AUTOSAR XML (schema 00050)
package /BMW/Boardnet/CommunicationClusters
  can cluster CAN_IPF_32: baudrate=500000, protocol-name=CAN
    can physical channel CAN_IPF_32: comm-connectors=[con_IPF_HVM_CAN_IPF_32, con_Wallbox_CHAdeMO_CAN_IPF_32]
      frame EAPC_CHDM_H100: id 0x100, from IPF_HVM, to Wallbox_CHAdeMO, category=APPLICATION, frame-length=8, can-addressing-mode=STANDARD, can-frame-rx-behavior=CAN-20, can-frame-tx-behavior=CAN-20
        pdu EAPC_CHDM_H100: length=8, transmission-mode-true-timing=cyclic-timing=time-period={tolerance=absolute-tolerance=0.01, value=0.1}, unused-bit-pattern=255  # @Symphony.CustomCommModePduGroup=EAPC_CHDM;
          signal EAPC_CHDM_MAX_BT_U: start 32, 8 bit, little-endian, data-type-policy=OVERRIDE, base-type=uint16, compu {identical; unit V} "EAPC_ChademoMaximumBatteryVoltage", range phys 0..600 V, to Wallbox_CHAdeMO  # EAPC_ChademoMaximumBatteryVoltage | LogicalInterface:BMW.INFRASTRUCTURE.HIGHVOLTAGE.Charging[internal]@Infrastruktur;
          mapping EAPC_CHDM_CHA_RATE_REF_CONST: i-signal=EAPC_CHDM_CHA_RATE_REF_CONST, packing-byte-order=little-endian, start-position=48
          signal EAPC_CHDM_CHA_RATE_TEST_GREE: start 8, 8 bit, little-endian, base-type=uint8
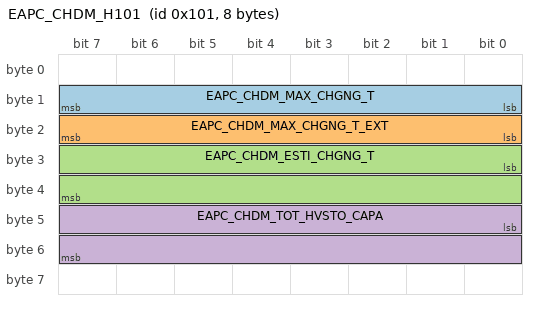
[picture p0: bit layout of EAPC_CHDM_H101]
      frame EAPC_CHDM_H101: id 0x101, from IPF_HVM, to Wallbox_CHAdeMO, category=APPLICATION, frame-length=8, can-addressing-mode=STANDARD, can-frame-rx-behavior=CAN-20, can-frame-tx-behavior=CAN-20
        pdu EAPC_CHDM_H101: length=8, transmission-mode-true-timing=cyclic-timing=time-period={tolerance=absolute-tolerance=0.01, value=0.1}, unused-bit-pattern=255  # @Symphony.CustomCommModePduGroup=EAPC_CHDM;
          signal EAPC_CHDM_MAX_CHGNG_T: start 8, 8 bit, little-endian, base-type=uint8, compu {phys=raw*10 for raw 0..255; unit s} "EAPC_ChademoMaximumChargingTime", range phys 0..2550 s, to Wallbox_CHAdeMO  # EAPC_ChademoMaximumChargingTime | LogicalInterface:BMW.INFRASTRUCTURE.HIGHVOLTAGE.Charging[internal]@Infrastruktur;
          signal EAPC_CHDM_MAX_CHGNG_T_EXT: start 16, 8 bit, little-endian, base-type=uint8, compu {identical; unit min} "EAPC_ChademoMaximumChargingTimeExtended", range phys 0..255 min, to Wallbox_CHAdeMO  # EAPC_ChademoMaximumChargingTimeExtended | LogicalInterface:BMW.INFRASTRUCTURE.HIGHVOLTAGE.Charging[internal]@Infrastruktur; Dieses Signal wird nur ausgewertet, wenn das Signal <<Maximum Charging Time>> den Wert FF aufweist. ========== LogicalInterface:BMW.INFRASTRUCTURE.HIGHVOLTAGE.Charging[internal]@Infrastruktur; This signal is evaluated only if the signal <<Maximum Charging Time>> has the value FF.
          signal EAPC_CHDM_ESTI_CHGNG_T: start 24, 16 bit, little-endian, base-type=uint16, compu {identical; unit min} "EAPC_ChademoEstimatedChargingTime", range phys 0..254 min, to Wallbox_CHAdeMO  # EAPC_ChademoEstimatedChargingTime | LogicalInterface:BMW.INFRASTRUCTURE.HIGHVOLTAGE.Charging[internal]@Infrastruktur; Dieses Signal wird nur für die Anzeige ausgewertet. Erwartete Zeitdauer bis zum Ladeende. ========== LogicalInterface:BMW.INFRASTRUCTURE.HIGHVOLTAGE.Charging[internal]@Infrastruktur; This signal is evaluated only for the display. Expected duration until the end of charging.
          signal EAPC_CHDM_TOT_HVSTO_CAPA: start 40, 16 bit, little-endian, base-type=uint16, compu {phys=raw*0.1 for raw 0..65535; unit kWh}, range phys 0..6553.5 kWh, to Wallbox_CHAdeMO  # EAPC_ChademoTotalCapacityOfTractionBatt | LogicalInterface:BMW.INFRASTRUCTURE.HIGHVOLTAGE.Charging[internal]@Infrastruktur; Kapazität des HV-Speichers ========== LogicalInterface:BMW.INFRASTRUCTURE.HIGHVOLTAGE.Charging[internal]@Infrastruktur; Capacitance of the high voltage battery
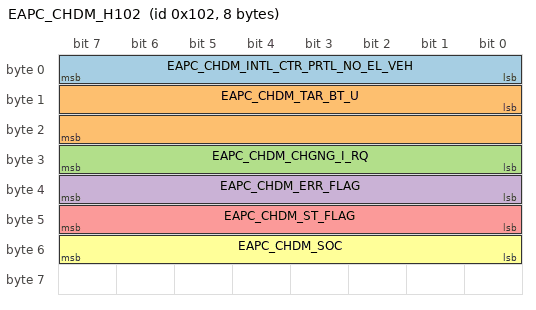
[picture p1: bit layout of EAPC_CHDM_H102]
      frame EAPC_CHDM_H102: id 0x102, from IPF_HVM, to Wallbox_CHAdeMO, category=APPLICATION, frame-length=8, can-addressing-mode=STANDARD, can-frame-rx-behavior=CAN-20, can-frame-tx-behavior=CAN-20
        pdu EAPC_CHDM_H102: length=8, transmission-mode-true-timing=cyclic-timing=time-period={tolerance=absolute-tolerance=0.01, value=0.1}, unused-bit-pattern=255  # @Symphony.CustomCommModePduGroup=EAPC_CHDM;
          signal EAPC_CHDM_INTL_CTR_PRTL_NO_EL_VEH: start 0, 8 bit, little-endian, base-type=uint8, compu {identical} "EAPC_ChademoInternalControlProtokolNumberElectricVehicle", range phys 0..255, to Wallbox_CHAdeMO  # EAPC_ChademoInternalControlProtocolNumberElectricVehicle | LogicalInterface:BMW.INFRASTRUCTURE.HIGHVOLTAGE.Charging[internal]@Infrastruktur;
          signal EAPC_CHDM_TAR_BT_U: start 8, 16 bit, little-endian, base-type=uint16, compu {identical; unit V} "EAPC_ChademoTargetBatteryVoltage", range phys 0..600 V, to Wallbox_CHAdeMO  # EAPC_ChademoTargetBatteryVoltage | LogicalInterface:BMW.INFRASTRUCTURE.HIGHVOLTAGE.Charging[internal]@Infrastruktur;
          signal EAPC_CHDM_CHGNG_I_RQ: start 24, 8 bit, little-endian, base-type=uint8, compu {identical; unit A} "EAPC_ChademoChargingCurrentRequest", range phys 0..255 A, to Wallbox_CHAdeMO  # EAPC_ChademoChargingCurrentRequest | LogicalInterface:BMW.INFRASTRUCTURE.HIGHVOLTAGE.Charging[internal]@Infrastruktur;
          signal EAPC_CHDM_ERR_FLAG: start 32, 8 bit, little-endian, base-type=uint8, compu {mask 1: 1=Battery_overvoltage (EAPC_CHDM_ERR_FLAG_Battery_overvoltage) ((0: normal, 1: occurrence)), mask 16: 16=Voltage_differential (EAPC_CHDM_ERR_FLAG_Voltage_differential) ((0: normal, 1: occurrence)), mask 2: 2=Battery_undervoltage (EAPC_CHDM_ERR_FLAG_Battery_undervoltage) ((0: normal, 1: occurrence)), mask 4: 4=Battery_current_differential (EAPC_CHDM_ERR_FLAG_Battery_current_differential) ((0: normal, 1: occurrence)), mask 8: 8=High_battery_temperature (EAPC_CHDM_ERR_FLAG_High_battery_temperature) ((0: normal, 1: occurrence))} "EAPC_ChademoErrorFlag", to Wallbox_CHAdeMO  # EAPC_ChademoErrorFlag | LogicalInterface:BMW.INFRASTRUCTURE.HIGHVOLTAGE.Charging[internal]@Infrastruktur;
          signal EAPC_CHDM_ST_FLAG: start 40, 8 bit, little-endian, base-type=uint8, compu {mask 1: 1=Vehicle_charging_enabled (EAPC_CHDM_ST_FLAG_Vehicle_charging_enabled) ((0: disenabled, 1: enabled)), mask 16: 16=Normal_stop_request_before_charging (EAPC_CHDM_ST_FLAG_Normal_stop_request_before_charging) ((0: No request 1: Stop request)), mask 2: 2=Vehicle_shift_position (EAPC_CHDM_ST_FLAG_Vehicle_shift_position) ((0: parking position, 1: other than the parking)), mask 4: 4=Charging_System_Fault (EAPC_CHDM_ST_FLAG_Charging_System_Fault) ((0: normal, 1:fault )), mask 8: 8=Vehicle_status (EAPC_CHDM_ST_FLAG_Vehicle_status) ((0: EV contactor close or during welding detection 1: EV contactor open or termination of welding detection))} "EAPC_ChademoStatusFlag", to Wallbox_CHAdeMO  # EAPC_ChademoStatusFlag | LogicalInterface:BMW.INFRASTRUCTURE.HIGHVOLTAGE.Charging[internal]@Infrastruktur;
          signal EAPC_CHDM_SOC: start 48, 8 bit, little-endian, base-type=uint8, compu {identical; unit %} "EAPC_ChademoRemainingQuantityBatteryCapacity", range phys 0..100 %, to Wallbox_CHAdeMO  # EAPC_ChademoStateOfCharge | LogicalInterface:BMW.INFRASTRUCTURE.HIGHVOLTAGE.Charging[internal]@Infrastruktur; Charged rate ========== LogicalInterface:BMW.INFRASTRUCTURE.HIGHVOLTAGE.Charging[internal]@Infrastruktur; Charged rate
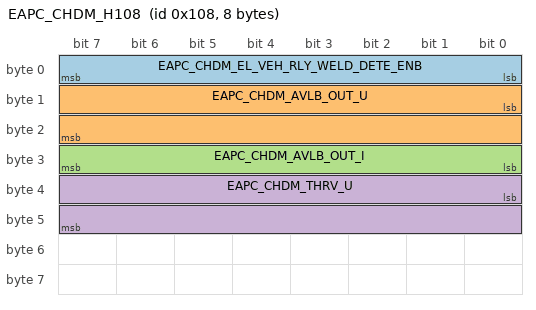
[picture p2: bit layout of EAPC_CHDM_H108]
      frame EAPC_CHDM_H108: id 0x108, from Wallbox_CHAdeMO, to IPF_HVM, category=APPLICATION, frame-length=8, can-addressing-mode=STANDARD, can-frame-rx-behavior=CAN-20, can-frame-tx-behavior=CAN-20
        pdu EAPC_CHDM_H108: length=8, transmission-mode-true-timing=cyclic-timing=time-period={tolerance=absolute-tolerance=0.01, value=0.1}, unused-bit-pattern=255  # @Symphony.CustomCommModePduGroup=EAPC_CHDM;
          signal EAPC_CHDM_EL_VEH_RLY_WELD_DETE_ENB: start 0, 8 bit, little-endian, base-type=uint8, compu {identical} "EAPC_ChademoElectricVehicleRelayWeldingDetectionEnable", range phys 0..255, to IPF_HVM CCU  # EAPC_ChademoElectricVehicleRelayWeldingDetectionEnable | LogicalInterface:BMW.INFRASTRUCTURE.HIGHVOLTAGE.Charging[internal]@Infrastruktur;
          signal EAPC_CHDM_AVLB_OUT_U: start 8, 16 bit, little-endian, base-type=uint16, compu {identical; unit V} "EAPC_ChademoAvailableOutputVoltage", range phys 0..600 V, to IPF_HVM CCU  # EAPC_ChademoAvailableOutputVoltage | LogicalInterface:BMW.INFRASTRUCTURE.HIGHVOLTAGE.Charging[internal]@Infrastruktur;
          signal EAPC_CHDM_AVLB_OUT_I: start 24, 8 bit, little-endian, base-type=uint8, compu {identical; unit A} "EAPC_ChademoAvailableOutputCurrent", range phys 0..255 A, to IPF_HVM CCU  # EAPC_ChademoAvailableOutputCurrent | LogicalInterface:BMW.INFRASTRUCTURE.HIGHVOLTAGE.Charging[internal]@Infrastruktur;
          signal EAPC_CHDM_THRV_U: start 32, 16 bit, little-endian, base-type=uint16, compu {identical; unit V} "EAPC_ChademoThresholdValueVoltage", range phys 0..600 V, to IPF_HVM CCU  # EAPC_ChademoThresholdValueVoltage | LogicalInterface:BMW.INFRASTRUCTURE.HIGHVOLTAGE.Charging[internal]@Infrastruktur;
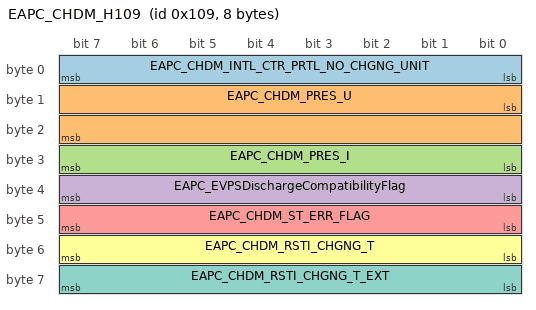
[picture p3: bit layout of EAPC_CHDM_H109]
      frame EAPC_CHDM_H109: id 0x109, from Wallbox_CHAdeMO, to IPF_HVM, category=APPLICATION, frame-length=8, can-addressing-mode=STANDARD, can-frame-rx-behavior=CAN-20, can-frame-tx-behavior=CAN-20
        pdu EAPC_CHDM_H109: length=8, transmission-mode-true-timing=cyclic-timing=time-period={tolerance=absolute-tolerance=0.01, value=0.1}, unused-bit-pattern=255  # @Symphony.CustomCommModePduGroup=EAPC_CHDM;
          signal EAPC_CHDM_INTL_CTR_PRTL_NO_CHGNG_UNIT: start 0, 8 bit, little-endian, base-type=uint8, compu {identical} "EAPC_ChademoInternalControlProtokolNumberChargingUnit", range phys 0..255, to IPF_HVM CCU  # EAPC_ChademoInternalControlProtokolNumberChargingUnit | LogicalInterface:BMW.INFRASTRUCTURE.HIGHVOLTAGE.Charging[internal]@Infrastruktur;
          signal EAPC_CHDM_PRES_U: start 8, 16 bit, little-endian, base-type=uint16, compu {identical; unit V} "EAPC_ChademoPresentVoltage", range phys 0..600 V, to IPF_HVM CCU  # EAPC_ChademoPresentVoltage | LogicalInterface:BMW.INFRASTRUCTURE.HIGHVOLTAGE.Charging[internal]@Infrastruktur;
          signal EAPC_CHDM_PRES_I: start 24, 8 bit, little-endian, base-type=uint8, compu {identical; unit A} "EAPC_ChademoPresentCurrent", range phys 0..255 A, to IPF_HVM CCU  # EAPC_ChademoPresentCurrent | LogicalInterface:BMW.INFRASTRUCTURE.HIGHVOLTAGE.Charging[internal]@Infrastruktur;
          signal EAPC_EVPSDischargeCompatibilityFlag: start 32, 8 bit, little-endian, base-type=uint8, invalid-value=value_255:255, compu {0=Incompatible (EAPC_EVPSDischargeCompatibilityFlag_Incompatible), 1=Compatible (EAPC_EVPSDischargeCompatibilityFlag_Compatible)}, range raw 0..1, to CCU  # Entladungskompatibilitätsflag EVPS; ========== Discharge compatibility flag EVPS
          signal EAPC_CHDM_ST_ERR_FLAG: start 40, 8 bit, little-endian, base-type=uint8, compu {mask 1: 1=Charger_status (EAPC_CHDM_ST_ERR_FLAG_Charger_status) ((0: standby, 1: charging)), mask 16: 16=Charging_system_malfunction (EAPC_CHDM_ST_ERR_FLAG_Charging_system_malfunction) ((0: normal, 1: malfunction)), mask 2: 2=Charger_malfunction (EAPC_CHDM_ST_ERR_FLAG_Charger_malfunction) ((0: normal, 1: malfunction)), mask 32: 32=Charging_stop_control (EAPC_CHDM_ST_ERR_FLAG_Charging_stop_control) ((0: trucking mode, 1: suppressing mode)), mask 4: 4=Charger_connector_lock (EAPC_CHDM_ST_ERR_FLAG_Charger_connector_lock) ((0: open, 1: locked)), mask 8: 8=Battery_incompatibility (EAPC_CHDM_ST_ERR_FLAG_Battery_incompatibility) ((0: compatible, 1: incompatible))} "EAPC_ChademoStatusErrorFlag", to IPF_HVM CCU  # EAPC_ChademoStatusErrorFlag | LogicalInterface:BMW.INFRASTRUCTURE.HIGHVOLTAGE.Charging[internal]@Infrastruktur;
          signal EAPC_CHDM_RSTI_CHGNG_T: start 48, 8 bit, little-endian, base-type=uint8, compu {phys=raw*10 for raw 0..255; unit s} "EAPC_ChademoResidualTimeChargingTime", range phys 0..2550 s, to IPF_HVM CCU  # EAPC_ChademoResidualTimeChargingTime | LogicalInterface:BMW.INFRASTRUCTURE.HIGHVOLTAGE.Charging[internal]@Infrastruktur;
          signal EAPC_CHDM_RSTI_CHGNG_T_EXT: start 56, 8 bit, little-endian, base-type=uint8, compu {identical; unit min} "EAPC_ChademoResidualTimeChargingTimeExtended", range phys 0..255 min, to IPF_HVM CCU  # EAPC_ChademoResidualTimeChargingTimeExtended | LogicalInterface:BMW.INFRASTRUCTURE.HIGHVOLTAGE.Charging[internal]@Infrastruktur;
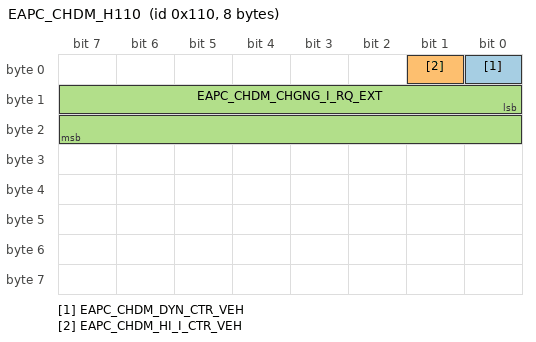
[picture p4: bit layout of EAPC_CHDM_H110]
      frame EAPC_CHDM_H110: id 0x110, from IPF_HVM, to Wallbox_CHAdeMO, category=APPLICATION, frame-length=8, can-addressing-mode=STANDARD, can-frame-rx-behavior=CAN-20, can-frame-tx-behavior=CAN-20
        pdu EAPC_CHDM_H110: length=8, transmission-mode-true-timing=cyclic-timing=time-period={tolerance=absolute-tolerance=0.01, value=0.1}, unused-bit-pattern=255  # @Symphony.CustomCommModePduGroup=EAPC_CHDM;
          signal EAPC_CHDM_DYN_CTR_VEH: start 0, 1 bit, little-endian, base-type=uint8, compu-method=EAPC_CHAdeMO_1, range raw 0..1, to Wallbox_CHAdeMO  # EAPC_ChademoDynamicControlVehicle | LogicalInterface:BMW.INFRASTRUCTURE.HIGHVOLTAGE.Charging[internal]@Infrastruktur; Unterstützung dynamische Regelung durch Fahrzeug ========== LogicalInterface:BMW.INFRASTRUCTURE.HIGHVOLTAGE.Charging[internal]@Infrastruktur; Support of dynamic control through vehicle
          signal EAPC_CHDM_HI_I_CTR_VEH: start 1, 1 bit, little-endian, base-type=uint8, compu-method=EAPC_CHAdeMO_1, range raw 0..1, to Wallbox_CHAdeMO  # EAPC_ChademoHighCurrentControlVehicle | LogicalInterface:BMW.INFRASTRUCTURE.HIGHVOLTAGE.Charging[internal]@Infrastruktur; Unterstützung hoher Ladeströme durch Fahrzeug ========== LogicalInterface:BMW.INFRASTRUCTURE.HIGHVOLTAGE.Charging[internal]@Infrastruktur; Support of high charging currents through vehicle
          signal EAPC_CHDM_CHGNG_I_RQ_EXT: start 8, 16 bit, little-endian, base-type=uint16, compu {identical; unit A}, range phys 0..1023 A, to Wallbox_CHAdeMO  # EAPC_ChademoChargingCurrentRequestExt | LogicalInterface:BMW.INFRASTRUCTURE.HIGHVOLTAGE.Charging[internal]@Infrastruktur; Angeforderder Ladestrom ========== LogicalInterface:BMW.INFRASTRUCTURE.HIGHVOLTAGE.Charging[internal]@Infrastruktur; Requested charging current
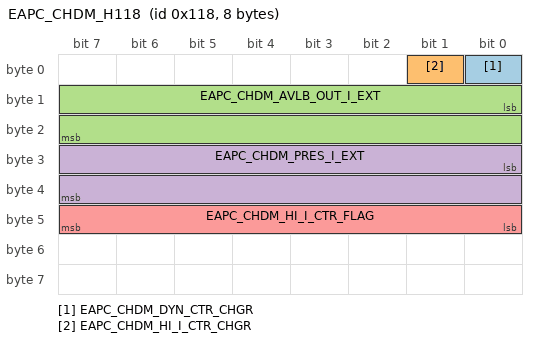
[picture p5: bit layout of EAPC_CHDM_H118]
      frame EAPC_CHDM_H118: id 0x118, from Wallbox_CHAdeMO, to IPF_HVM, category=APPLICATION, frame-length=8, can-addressing-mode=STANDARD, can-frame-rx-behavior=CAN-20, can-frame-tx-behavior=CAN-20
        pdu EAPC_CHDM_H118: length=8, transmission-mode-true-timing=cyclic-timing=time-period={tolerance=absolute-tolerance=0.01, value=0.1}, unused-bit-pattern=255  # @Symphony.CustomCommModePduGroup=EAPC_CHDM;
          signal EAPC_CHDM_DYN_CTR_CHGR: start 0, 1 bit, little-endian, base-type=uint8, compu-method=EAPC_CHAdeMO_1, range raw 0..1, to IPF_HVM CCU  # EAPC_ChademoDynamicControlCharger | LogicalInterface:BMW.INFRASTRUCTURE.HIGHVOLTAGE.Charging[internal]@Infrastruktur; Unterstützung dynamische Regelung durch Ladestation ========== LogicalInterface:BMW.INFRASTRUCTURE.HIGHVOLTAGE.Charging[internal]@Infrastruktur; Support of dynamic control through charging station
          signal EAPC_CHDM_HI_I_CTR_CHGR: start 1, 1 bit, little-endian, base-type=uint8, compu-method=EAPC_CHAdeMO_1, range raw 0..1, to IPF_HVM CCU  # EAPC_ChademoHighCurrentControlCharger | LogicalInterface:BMW.INFRASTRUCTURE.HIGHVOLTAGE.Charging[internal]@Infrastruktur; Unterstützung hoher Ladeströme durch Ladestation ========== LogicalInterface:BMW.INFRASTRUCTURE.HIGHVOLTAGE.Charging[internal]@Infrastruktur; Support of high charging currents through charging station
          signal EAPC_CHDM_AVLB_OUT_I_EXT: start 8, 16 bit, little-endian, base-type=uint16, compu {identical; unit A}, range phys 0..1023 A, to IPF_HVM CCU  # EAPC_ChademoAvailableOutputCurrentExt | LogicalInterface:BMW.INFRASTRUCTURE.HIGHVOLTAGE.Charging[internal]@Infrastruktur; Verfügbarer Ladestrom ========== LogicalInterface:BMW.INFRASTRUCTURE.HIGHVOLTAGE.Charging[internal]@Infrastruktur; Available charging current
          signal EAPC_CHDM_PRES_I_EXT: start 24, 16 bit, little-endian, base-type=uint16, compu {identical; unit A}, range phys 0..1023 A, to IPF_HVM CCU  # EAPC_ChademoPresentChargingCurrentExt | LogicalInterface:BMW.INFRASTRUCTURE.HIGHVOLTAGE.Charging[internal]@Infrastruktur; Aktueller Ladestrom ========== LogicalInterface:BMW.INFRASTRUCTURE.HIGHVOLTAGE.Charging[internal]@Infrastruktur; Current charging current
          signal EAPC_CHDM_HI_I_CTR_FLAG: start 40, 8 bit, little-endian, base-type=uint8, compu {mask 1: 1=Operating_condition (EAPC_HighCurrentControlCondFlags_Operating_condition), mask 16: 16=Current_limiting_function_charging_connector (EAPC_HighCurrentControlCondFlags_Current_limiting_function_charging_connector), mask 2: 2=Cooling_function_charging_cable (EAPC_HighCurrentControlCondFlags_Cooling_function_charging_cable), mask 32: 32=Over_temperature_protection_charging_connector (EAPC_HighCurrentControlCondFlags_Over_temperature_protection_charging_connector), mask 4: 4=Current_limiting_function_charging_cable (EAPC_HighCurrentControlCondFlags_Current_limiting_function_charging_cable), mask 64: 64=Reliability_design_temperature_monitoring (EAPC_HighCurrentControlCondFlags_Reliability_design_temperature_monitoring), mask 8: 8=Cooling_function_charging_connector (EAPC_HighCurrentControlCondFlags_Cooling_function_charging_connector)}, to IPF_HVM CCU  # EAPC_ChademoHighCurrentControlCondFlags | LogicalInterface:BMW.INFRASTRUCTURE.HIGHVOLTAGE.Charging[internal]@Infrastruktur; Flags zur Überwachung des Hochstromladens ========== LogicalInterface:BMW.INFRASTRUCTURE.HIGHVOLTAGE.Charging[internal]@Infrastruktur; Flags for monitoring the high-current charging
  can cluster EAPC_DC_CAN: baudrate=500000, protocol-name=CAN
    can physical channel EAPC_DC_CAN: comm-connectors=[con_CCU_EAPC_DC_CAN, con_Wallbox_CHAdeMO_EAPC_DC_CAN]
      frame EAPC_CHDM_H100: id 0x100, from CCU, to Wallbox_CHAdeMO, category=APPLICATION, frame-length=8, can-addressing-mode=STANDARD, can-frame-rx-behavior=CAN-20, can-frame-tx-behavior=CAN-20
        carries pdu EAPC_CHDM_H100: packing-byte-order=little-endian, start-position=0
      frame EAPC_CHDM_H101: id 0x101, from CCU, to Wallbox_CHAdeMO, category=APPLICATION, frame-length=8, can-addressing-mode=STANDARD, can-frame-rx-behavior=CAN-20, can-frame-tx-behavior=CAN-20
        carries pdu EAPC_CHDM_H101: packing-byte-order=little-endian, start-position=0
      frame EAPC_CHDM_H102: id 0x102, from CCU, to Wallbox_CHAdeMO, category=APPLICATION, frame-length=8, can-addressing-mode=STANDARD, can-frame-rx-behavior=CAN-20, can-frame-tx-behavior=CAN-20
        carries pdu EAPC_CHDM_H102: packing-byte-order=little-endian, start-position=0
      frame EAPC_CHDM_H108: id 0x108, from Wallbox_CHAdeMO, to CCU, category=APPLICATION, frame-length=8, can-addressing-mode=STANDARD, can-frame-rx-behavior=CAN-20, can-frame-tx-behavior=CAN-20
        carries pdu EAPC_CHDM_H108: packing-byte-order=little-endian, start-position=0
      frame EAPC_CHDM_H109: id 0x109, from Wallbox_CHAdeMO, to CCU, category=APPLICATION, frame-length=8, can-addressing-mode=STANDARD, can-frame-rx-behavior=CAN-20, can-frame-tx-behavior=CAN-20
        carries pdu EAPC_CHDM_H109: packing-byte-order=little-endian, start-position=0
      frame EAPC_CHDM_H110: id 0x110, from CCU, to Wallbox_CHAdeMO, category=APPLICATION, frame-length=8, can-addressing-mode=STANDARD, can-frame-rx-behavior=CAN-20, can-frame-tx-behavior=CAN-20
        carries pdu EAPC_CHDM_H110: packing-byte-order=little-endian, start-position=0
      frame EAPC_CHDM_H118: id 0x118, from Wallbox_CHAdeMO, to CCU, category=APPLICATION, frame-length=8, can-addressing-mode=STANDARD, can-frame-rx-behavior=CAN-20, can-frame-tx-behavior=CAN-20
        carries pdu EAPC_CHDM_H118: packing-byte-order=little-endian, start-position=0
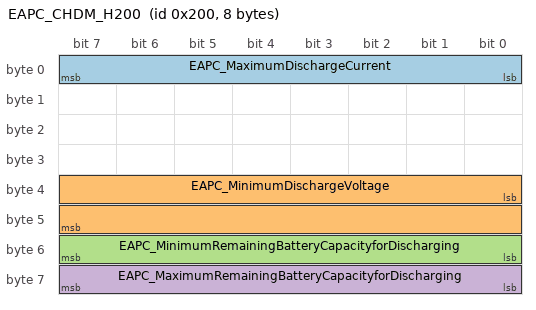
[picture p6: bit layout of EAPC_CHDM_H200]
      frame EAPC_CHDM_H200: id 0x200, from CCU, to Wallbox_CHAdeMO, category=APPLICATION, frame-length=8, can-addressing-mode=STANDARD, can-frame-rx-behavior=CAN-20, can-frame-tx-behavior=CAN-20  # EAPC_DC_CAN
        pdu EAPC_CHDM_H200: length=8, transmission-mode-true-timing=cyclic-timing=time-period={tolerance=absolute-tolerance=0.01, value=0.1}, unused-bit-pattern=255
          signal EAPC_MaximumDischargeCurrent: start 0, 8 bit, little-endian, base-type=uint8, invalid-value=value_255:255, compu {phys=raw-255 for raw 0..255; unit A}, range phys -255..0 A, to Wallbox_CHAdeMO  # Maximaler Entladestrom des Fahrzeugs; ========== Maximum discharge current of the vehicle;
          signal EAPC_MinimumDischargeVoltage: start 32, 16 bit, little-endian, base-type=uint16, invalid-value=value_65535:65535, compu {identical; unit V}, range phys 0..600 V, to Wallbox_CHAdeMO  # Minimale Entladespannung des Fahrzeugs; ========== Minimum discharge voltage of the vehicle;
          signal EAPC_MinimumRemainingBatteryCapacityforDischarging: start 48, 8 bit, little-endian, base-type=uint8, invalid-value=value_255:255, compu {identical; unit %}, range phys 0..100 %, to Wallbox_CHAdeMO  # Minimale verbleibende Batteriekapazität zum Entladen; ========== Minimum remaining battery capacity to discharge;
          signal EAPC_MaximumRemainingBatteryCapacityforDischarging: start 56, 8 bit, little-endian, base-type=uint8, invalid-value=value_255:255, compu {identical; unit %}, range phys 0..100 %, to Wallbox_CHAdeMO  # Maximale verbleibende Batteriekapazität zum Entladen; ========== Maximum remaining battery capacity to discharge;
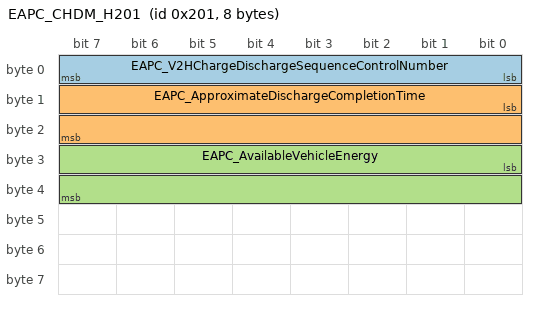
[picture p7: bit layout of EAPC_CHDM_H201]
      frame EAPC_CHDM_H201: id 0x201, from CCU, to Wallbox_CHAdeMO, category=APPLICATION, frame-length=8, can-addressing-mode=STANDARD, can-frame-rx-behavior=CAN-20, can-frame-tx-behavior=CAN-20  # EAPC_DC_CAN
        pdu EAPC_CHDM_H201: length=8, transmission-mode-true-timing=cyclic-timing=time-period={tolerance=absolute-tolerance=0.01, value=0.1}, unused-bit-pattern=255
          signal EAPC_V2HChargeDischargeSequenceControlNumber: start 0, 8 bit, little-endian, base-type=uint8, invalid-value=value_255:255, compu {identical}, range phys 0..255, to Wallbox_CHAdeMO  # V2H Sequenz Kontrollnummer Fahrzeug; ========== V2H sequence control number vehicle;
          signal EAPC_ApproximateDischargeCompletionTime: start 8, 16 bit, little-endian, base-type=uint16, invalid-value=value_65535:65535, compu {phys=raw-1 for raw 0..65535; unit min}, range phys -1..65534 min, to Wallbox_CHAdeMO  # Voraussichtliche Entladungs-Abschlusszeit; ========== Expected discharge completion time;
          signal EAPC_AvailableVehicleEnergy: start 24, 16 bit, little-endian, base-type=uint16, invalid-value=value_65535:65535, compu {phys=raw*0.1-0.1 for raw 0..65535; unit kWh}, range phys -0.1..6553.4 kWh, to Wallbox_CHAdeMO  # Verfügbare Fahrzeugenergie; ========== Available vehicle energy;
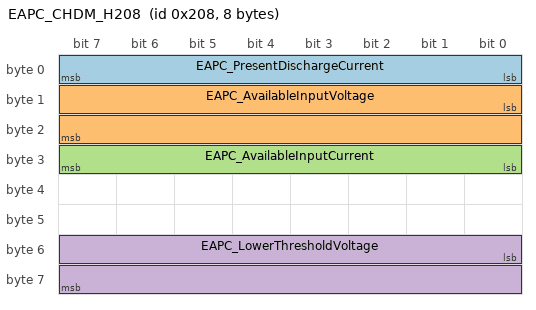
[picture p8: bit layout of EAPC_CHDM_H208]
      frame EAPC_CHDM_H208: id 0x208, from Wallbox_CHAdeMO, to CCU, category=APPLICATION, frame-length=8, can-addressing-mode=STANDARD, can-frame-rx-behavior=CAN-20, can-frame-tx-behavior=CAN-20  # EAPC_DC_CAN
        pdu EAPC_CHDM_H208: length=8, transmission-mode-true-timing=cyclic-timing=time-period={tolerance=absolute-tolerance=0.01, value=0.1}, unused-bit-pattern=255
          signal EAPC_PresentDischargeCurrent: start 0, 8 bit, little-endian, base-type=uint8, invalid-value=value_255:255, compu {phys=raw-255 for raw 0..255; unit A}, range phys -255..0 A, to CCU  # Aktueller Entladestrom; ========== Current discharge current;
          signal EAPC_AvailableInputVoltage: start 8, 16 bit, little-endian, base-type=uint16, invalid-value=value_65535:65535, compu {identical; unit V}, range phys 0..600 V, to CCU  # Verfügbare Eingangsspannung; ========== Available input voltage;
          signal EAPC_AvailableInputCurrent: start 24, 8 bit, little-endian, base-type=uint8, invalid-value=value_255:255, compu {phys=raw-255 for raw 0..255; unit A}, range phys -255..0 A, to CCU  # Verfügbarer Eingangsstrom; ========== Available input current;
          signal EAPC_LowerThresholdVoltage: start 48, 16 bit, little-endian, base-type=uint16, invalid-value=value_65535:65535, compu {identical; unit V}, range phys 0..600 V, to CCU  # Untere Spannungsschwelle; ========== Lower voltage threshold;
      frame EAPC_CHDM_H209: id 0x209, from Wallbox_CHAdeMO, to CCU, category=APPLICATION, frame-length=8, can-addressing-mode=STANDARD, can-frame-rx-behavior=CAN-20, can-frame-tx-behavior=CAN-20  # EAPC_DC_CAN
        pdu EAPC_CHDM_H209: length=8, transmission-mode-true-timing=cyclic-timing=time-period={tolerance=absolute-tolerance=0.01, value=0.1}, unused-bit-pattern=255
          signal EAPC_V2HChargeDischargeSequenceControlNumberEVPS: start 0, 8 bit, little-endian, base-type=uint8, invalid-value=value_255:255, compu {identical}, range phys 0..255, to CCU  # V2H Sequenz Kontrollnummer EVPS; ========== V2H sequence control number EVPS
          signal EAPC_RemainingDischargingTime: start 8, 16 bit, little-endian, base-type=uint16, invalid-value=value_65535:65535, compu {phys=raw-1 for raw 0..65535; unit min}, range phys -1..65534 min, to CCU  # Verbleibende Entladezeit; ========== Remaining discharge time
package /BMW/Boardnet/CompuMethods
  compu method EAPC_CHAdeMO_1: 0=Incompatible (EAPC_CHAdeMO_1_Incompatible), 1=Compatible (EAPC_CHAdeMO_1_Compatible)
package /BMW/Boardnet/EcuComposition/CCUComposition
  composition sw component type CCU_CPUComponent
package /BMW/Boardnet/EcuComposition/IPF_HVMComposition
  composition sw component type IPF_HVM_CPUComponent
package /BMW/Boardnet/EcuComposition/Wallbox_CHAdeMOComposition
  composition sw component type Wallbox_CHAdeMO_CPUComponent
package /BMW/Boardnet/EcuInstances
  ecu instance CCU: associated-com-i-pdu-group=[CCU_IN_PduGroup_EAPC_CHDM, CCU_OUT_PduGroup_EAPC_CHDM], client-id-range={lower-limit=14848, upper-limit=15103}, diagnostic-address=58, sleep-mode-supported=false, wake-up-over-bus-supported=false  # Combined_Charging_Unit | Steuergerät für Integrationsplattform E-Antrieb mit integrierter Ladefunktionalität und DCDC-Wandler HV 12V $AUTHORIZED_SECOC_KEYS: (0x0006, 0x0007, 0x0008, 0x0009, 0x000A, 0x000D, 0x000E, 0x5ECC, 0xDEFA)
    can communication controller Ctrl_CCU_EAPC_DC_CAN: can-controller-attributes=can-controller-configuration={prop-seg=49, sync-jump-width=15, time-seg-1=15, time-seg-2=15}  # CCU_EAPC_DC_CAN
    can communication connector con_CCU_EAPC_DC_CAN: comm-controller=Ctrl_CCU_EAPC_DC_CAN
  ecu instance IPF_HVM: associated-com-i-pdu-group=[IPF_HVM_IN_PduGroup_EAPC_CHDM, IPF_HVM_OUT_PduGroup_EAPC_CHDM], client-id-range={lower-limit=15616, upper-limit=15871}, diagnostic-address=61, sleep-mode-supported=false, wake-up-over-bus-supported=false  # Integrationsplattform_Fahren_Hochvolt_Management_und_Laden | $AUTHORIZED_SECOC_KEYS: (0x0006, 0x0008, 0x5ECC, 0xDEFA)
    can communication controller Ctrl_IPF_HVM_CAN_IPF_32: can-controller-attributes=can-controller-configuration={prop-seg=49, sync-jump-width=15, time-seg-1=15, time-seg-2=15}  # IPF_HVM_CAN_IPF_32
    can communication connector con_IPF_HVM_CAN_IPF_32: comm-controller=Ctrl_IPF_HVM_CAN_IPF_32
  ecu instance Wallbox_CHAdeMO: associated-com-i-pdu-group=[Wallbox_CHAdeMO_IN_PduGroup_EAPC_CHDM, Wallbox_CHAdeMO_OUT_PduGroup_EAPC_CHDM], sleep-mode-supported=false, wake-up-over-bus-supported=false
    can communication controller Ctrl_Wallbox_CHAdeMO_CAN_IPF_32: can-controller-attributes=can-controller-configuration={prop-seg=49, sync-jump-width=15, time-seg-1=15, time-seg-2=15}  # Wallbox_CHAdeMO_CAN_IPF_32
    can communication controller Ctrl_Wallbox_CHAdeMO_EAPC_DC_CAN: can-controller-attributes=can-controller-configuration={prop-seg=49, sync-jump-width=15, time-seg-1=15, time-seg-2=15}  # Wallbox_CHAdeMO_EAPC_DC_CAN
    can communication connector con_Wallbox_CHAdeMO_CAN_IPF_32: comm-controller=Ctrl_Wallbox_CHAdeMO_CAN_IPF_32
    can communication connector con_Wallbox_CHAdeMO_EAPC_DC_CAN: comm-controller=Ctrl_Wallbox_CHAdeMO_EAPC_DC_CAN
package /BMW/Boardnet/ISignalIPduGroups/CCU
  i signal i pdu group CCU_IN_PduGroup_EAPC_CHDM: communication-direction=IN, communication-mode=EAPC_CHDM, i-signal-i-pdus=[EAPC_CHDM_H108, EAPC_CHDM_H109, EAPC_CHDM_H118]
  i signal i pdu group CCU_OUT_PduGroup_EAPC_CHDM: communication-direction=OUT, communication-mode=EAPC_CHDM, i-signal-i-pdus=[EAPC_CHDM_H100, EAPC_CHDM_H101, EAPC_CHDM_H102, EAPC_CHDM_H110]
package /BMW/Boardnet/ISignalIPduGroups/IPF_HVM
  i signal i pdu group IPF_HVM_IN_PduGroup_EAPC_CHDM: communication-direction=IN, communication-mode=EAPC_CHDM, i-signal-i-pdus=[EAPC_CHDM_H108, EAPC_CHDM_H109, EAPC_CHDM_H118]
  i signal i pdu group IPF_HVM_OUT_PduGroup_EAPC_CHDM: communication-direction=OUT, communication-mode=EAPC_CHDM, i-signal-i-pdus=[EAPC_CHDM_H100, EAPC_CHDM_H101, EAPC_CHDM_H102, EAPC_CHDM_H110]
package /BMW/Boardnet/ISignalIPduGroups/Wallbox_CHAdeMO
  i signal i pdu group Wallbox_CHAdeMO_IN_PduGroup_EAPC_CHDM: communication-direction=IN, communication-mode=EAPC_CHDM, i-signal-i-pdus=[EAPC_CHDM_H100, EAPC_CHDM_H101, EAPC_CHDM_H102, EAPC_CHDM_H110]
  i signal i pdu group Wallbox_CHAdeMO_OUT_PduGroup_EAPC_CHDM: communication-direction=OUT, communication-mode=EAPC_CHDM, i-signal-i-pdus=[EAPC_CHDM_H108, EAPC_CHDM_H109, EAPC_CHDM_H118]
package /BMW/Boardnet/ISignals/EAPC_CHDM_H100
  i signal EAPC_CHDM_MIN_I_CHGNG: length=8, base-type=uint8, system-signal=EAPC_CHDM_MIN_I_CHGNG
package /BMW/Boardnet/SystemSignals
  system signal EAPC_CHDM_CHA_RATE_REF_CONST: compu {identical; unit %} "EAPC_ChademoTotalBatteryCapacity", range phys 0..100 %  # EAPC_ChademoChargedRateReferenceConstant | LogicalInterface:BMW.INFRASTRUCTURE.HIGHVOLTAGE.Charging[internal]@Infrastruktur; Charged rate reference constant ========== LogicalInterface:BMW.INFRASTRUCTURE.HIGHVOLTAGE.Charging[internal]@Infrastruktur; Charged rate reference constant
  system signal EAPC_CHDM_MIN_I_CHGNG: compu {identical; unit A}, range phys 0..200 A  # EAPC_ChademoMinimumChargeCurrent | LogicalInterface:BMW.INFRASTRUCTURE.HIGHVOLTAGE.Charging[internal]@Infrastruktur; Minimaler Ladestrom des Fahrzeugs ========== LogicalInterface:BMW.INFRASTRUCTURE.HIGHVOLTAGE.Charging[internal]@Infrastruktur; Minimum charging current of the vehicle
package /BMW/SystemComposition
  composition sw component type SystemComponent
    component CCU_CPUInstance: type=CCU_CPUComponent
    component IPF_HVM_CPUInstance: type=IPF_HVM_CPUComponent
    component Wallbox_CHAdeMO_CPUInstance: type=Wallbox_CHAdeMO_CPUComponent
package /BMW/Units
  6 x unit, all with offset-si-to-unit=0.0:
    ampere: display-name=A, factor-si-to-unit=1.0, physical-dimension=A1_0  # I1
    kilowatt_hour: display-name=kWh, factor-si-to-unit=2.7777777777777776E-7, physical-dimension=kg1_0_m2_0_secMinus2_0  # M1Len2TiNeg2
    minute: display-name=min, factor-si-to-unit=0.016666666666666666, physical-dimension=sec1_0  # Ti1
    percent: display-name=%, factor-si-to-unit=100.0, physical-dimension=PhysicalDimensions/NoDimension  # NoUnit
    second: display-name=s, factor-si-to-unit=1.0, physical-dimension=sec1_0  # Ti1
    volt: display-name=V, factor-si-to-unit=1.0, physical-dimension=AMinus1_0_kg1_0_m2_0_secMinus3_0  # INeg1M1Len2TiNeg3
package /BMW/Units/PhysicalDimensions
  5 x physical dimension, all with temperature-exp=0.0, molar-amount-exp=0.0, luminous-intensity-exp=0.0:
    A1_0: length-exp=0.0, mass-exp=0.0, time-exp=0.0, current-exp=1.0
    AMinus1_0_kg1_0_m2_0_secMinus3_0: length-exp=2.0, mass-exp=1.0, time-exp=-3.0, current-exp=-1.0
    NoDimension: length-exp=0.0, mass-exp=0.0, time-exp=0.0, current-exp=0.0
    kg1_0_m2_0_secMinus2_0: length-exp=2.0, mass-exp=1.0, time-exp=-2.0, current-exp=0.0
    sec1_0: length-exp=0.0, mass-exp=0.0, time-exp=1.0, current-exp=0.0
package /SymphonyAutosarUnits
  unit NoUnit: display-name=-, factor-si-to-unit=1.0, offset-si-to-unit=0.0, physical-dimension=PhysicalDimensions/NoDimension
package /SymphonyAutosarUnits/PhysicalDimensions
  physical dimension NoDimension: length-exp=0.0, mass-exp=0.0, time-exp=0.0, current-exp=0.0, temperature-exp=0.0, molar-amount-exp=0.0, luminous-intensity-exp=0.0
package /Systems
  system Bus_System_CAN_IPF_32_EAPC_DC_CAN: category=SYSTEM_EXTRACT, ecu-extract-version=0.0.1, pnc-vector-length=6, pnc-vector-offset=2, system-version=0.0.1
    system mapping Systems_SwcToEcuMapping
      sw-mappings:
        swc to ecu mapping CCU_CPUInstance: component=SystemComponentPrototype.CCU_CPUInstance, ecu-instance=CCU
        swc to ecu mapping IPF_HVM_CPUInstance: component=SystemComponentPrototype.IPF_HVM_CPUInstance, ecu-instance=IPF_HVM
        swc to ecu mapping Wallbox_CHAdeMO_CPUInstance: component=SystemComponentPrototype.Wallbox_CHAdeMO_CPUInstance, ecu-instance=Wallbox_CHAdeMO
    root-software-compositions:
      root sw composition prototype SystemComponentPrototype: software-composition=SystemComponent
package /Systems/Collections
  collection CCU_CCU_PHEV: category=FAMILY, element=CCU
package /Systems/ModeDeclarationGroups/BasePartialNetworks
  mode declaration group PWFVehicleState: initial-mode=KEINE_KOMMUNIKATION
    mode KEINE_KOMMUNIKATION
    mode UNGUELTIG
  mode declaration group UNGUELTIG: initial-mode=UNGUELTIG/UNGUELTIG_OFF
    mode UNGUELTIG_OFF
    mode UNGUELTIG_ON
package /Systems/ModeDeclarationGroups/FunctionalPartialNetworks
  mode declaration group Ungueltig: initial-mode=Ungueltig/UNGUELTIG_OFF
    mode UNGUELTIG_OFF
    mode UNGUELTIG_ON
